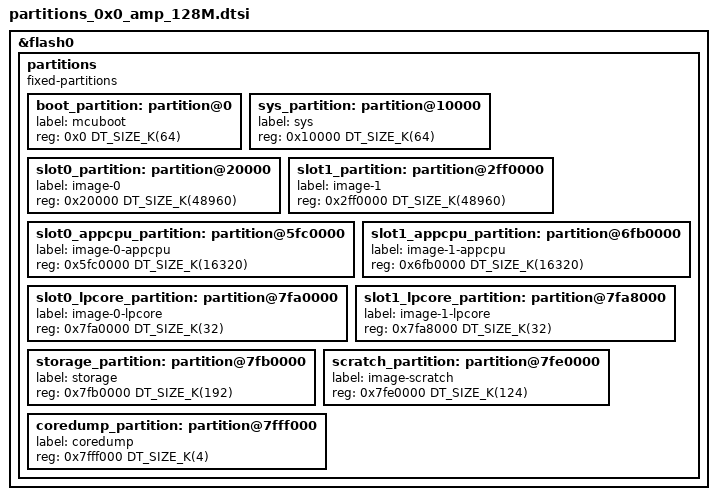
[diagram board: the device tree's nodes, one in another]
/*
 * Copyright (c) 2024-2025 Espressif Systems (Shanghai) Co., Ltd.
 *
 * SPDX-License-Identifier: Apache-2.0
 */

&flash0 {
	partitions {
		compatible = "fixed-partitions";
		#address-cells = <1>;
		#size-cells = <1>;

		boot_partition: partition@0 {
			label = "mcuboot";
			reg = <0x0 DT_SIZE_K(64)>;
		};

		sys_partition: partition@10000 {
			label = "sys";
			reg = <0x10000 DT_SIZE_K(64)>;
		};

		slot0_partition: partition@20000 {
			label = "image-0";
			reg = <0x20000 DT_SIZE_K(48960)>;
		};

		slot1_partition: partition@2ff0000 {
			label = "image-1";
			reg = <0x2ff0000 DT_SIZE_K(48960)>;
		};

		slot0_appcpu_partition: partition@5fc0000 {
			label = "image-0-appcpu";
			reg = <0x5fc0000 DT_SIZE_K(16320)>;
		};

		slot1_appcpu_partition: partition@6fb0000 {
			label = "image-1-appcpu";
			reg = <0x6fb0000 DT_SIZE_K(16320)>;
		};

		slot0_lpcore_partition: partition@7fa0000 {
			label = "image-0-lpcore";
			reg = <0x7fa0000 DT_SIZE_K(32)>;
		};

		slot1_lpcore_partition: partition@7fa8000 {
			label = "image-1-lpcore";
			reg = <0x7fa8000 DT_SIZE_K(32)>;
		};

		storage_partition: partition@7fb0000 {
			label = "storage";
			reg = <0x7fb0000 DT_SIZE_K(192)>;
		};

		scratch_partition: partition@7fe0000 {
			label = "image-scratch";
			reg = <0x7fe0000 DT_SIZE_K(124)>;
		};

		coredump_partition: partition@7fff000 {
			label = "coredump";
			reg = <0x7fff000 DT_SIZE_K(4)>;
		};
	};
};

/* Remaining flash size is 0kB
 * Last used address is 0x7FFFFFF
 */
